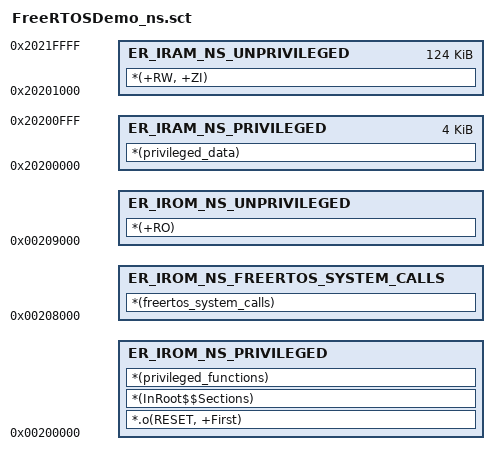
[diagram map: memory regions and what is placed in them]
; *************************************************************
; *** Scatter-Loading Description File generated by uVision ***
; *************************************************************

; Privileged Code:
;   Start   : 0x00200000
;   End     : 0x00208000 - 1
;   Size    : 32 Kbytes
;
; Privileged Data:
;   Start   : 0x20200000
;   End     : 0x20201000 - 1
;   Size    : 4 Kbytes
LR_IROM_NS_PRIVILEGED 0x00200000 0x00008000 ; load region size_region
{
    ER_IROM_NS_PRIVILEGED +0 ; load address = execution address
    {
        *.o(RESET, +First)
        *(InRoot$$Sections) ; All sections that must be in a root region
        *(privileged_functions)
    }

    ER_IRAM_NS_PRIVILEGED 0x20200000 0x00001000
    {
        *(privileged_data)
    }
}

; FreeRTOS System Calls:
;   Start   : 0x00208000
;   End     : 0x00209000 - 1
;   Size    : 4 Kbytes
LR_IROM_NS_FREERTOS_SYSTEM_CALLS 0x00208000 0x00001000 ; load region size_region
{
    ER_IROM_NS_FREERTOS_SYSTEM_CALLS +0 ; load address = execution address
    {
         *(freertos_system_calls)
    }
}

; Unprivileged Code:
;   Start   : 0x00209000
;   End     : 0x00400000 - 1
;   Size    : 2012 Kbytes
;
; Unprivileged Data:
;   Start   : 0x20201000
;   End     : 0x20220000 - 1
;   Size    : 124 Kbytes
LR_IROM_NS_UNPRIVILEGED 0x00209000 0x001F7000 ; load region size_region
{
    ER_IROM_NS_UNPRIVILEGED +0 ; load address = execution address
    {
         *(+RO)
    }

    ER_IRAM_NS_UNPRIVILEGED 0x20201000 0x0001F000
    {
        *(+RW, +ZI)
    }
}
